# MK66F18 register map
Vendor: NXP Semiconductors; Series: Kinetis_K; File version: 1.6
CPU: CM4 r0p1, little endian, no MPU, FPU, VTOR, 4 interrupt priority bits
Registers are 32-bit, read-write, reset 0x0 unless marked. A register's access mark holds for its fields unless they carry their own. Offsets are from the block's base; [hi:lo] are bit positions; {n}, {i} and the like mark numbered series.

## CMT — Carrier Modulator Transmitter
Base 0x40062000; register names take the prefix CMT_
0x00 CGH1 8-bit reset not defined — CMT Carrier Generator High Data Register 1
  [7:0] PH — Primary Carrier High Time Data Value
0x01 CGL1 8-bit reset not defined — CMT Carrier Generator Low Data Register 1
  [7:0] PL — Primary Carrier Low Time Data Value
0x02 CGH2 8-bit reset not defined — CMT Carrier Generator High Data Register 2
  [7:0] SH — Secondary Carrier High Time Data Value
0x03 CGL2 8-bit reset not defined — CMT Carrier Generator Low Data Register 2
  [7:0] SL — Secondary Carrier Low Time Data Value
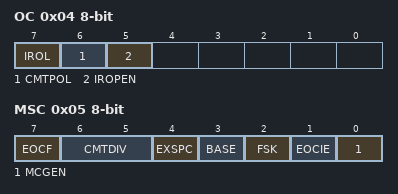
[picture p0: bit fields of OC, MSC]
0x04 OC 8-bit — CMT Output Control Register
  [7] IROL — IRO Latch Control
  [6] CMTPOL — CMT Output Polarity
    0=The IRO signal is active-low; 1=The IRO signal is active-high
  [5] IROPEN — IRO Pin Enable
    0=The IRO signal is disabled; 1=The IRO signal is enabled as output
0x05 MSC 8-bit — CMT Modulator Status and Control Register
  [7] EOCF ro — End Of Cycle Status Flag
    0=End of modulation cycle has not occurred since the flag last cleared; 1=End of modulator cycle has occurred
  [6:5] CMTDIV — CMT Clock Divide Prescaler
    0=IF * 1; 1=IF * 2; 2=IF * 4; 3=IF * 8
  [4] EXSPC — Extended Space Enable
    0=Extended space is disabled; 1=Extended space is enabled
  [3] BASE — Baseband Enable
    0=Baseband mode is disabled; 1=Baseband mode is enabled
  [2] FSK — FSK Mode Select
    0=The CMT operates in Time or Baseband mode; 1=The CMT operates in FSK mode
  [1] EOCIE — End of Cycle Interrupt Enable
    0=CPU interrupt is disabled; 1=CPU interrupt is enabled
  [0] MCGEN — Modulator and Carrier Generator Enable
    0=Modulator and carrier generator disabled; 1=Modulator and carrier generator enabled
0x06 CMD1 8-bit reset not defined — CMT Modulator Data Register Mark High
  [7:0] MB — MB[15:8]
0x07 CMD2 8-bit reset not defined — CMT Modulator Data Register Mark Low
  [7:0] MB — MB[7:0]
0x08 CMD3 8-bit reset not defined — CMT Modulator Data Register Space High
  [7:0] SB — SB[15:8]
0x09 CMD4 8-bit reset not defined — CMT Modulator Data Register Space Low
  [7:0] SB — SB[7:0]
0x0A PPS 8-bit — CMT Primary Prescaler Register
  [3:0] PPSDIV — Primary Prescaler Divider
    {v}=Bus clock * {v+1} (v=0..15)
0x0B DMA 8-bit — CMT Direct Memory Access Register
  [0] DMA — DMA Enable
    0=DMA transfer request and done are disabled; 1=DMA transfer request and done are enabled

## OSC — Oscillator
Base 0x40065000; register names take the prefix OSC_
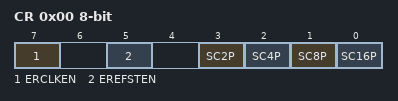
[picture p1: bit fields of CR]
0x00 CR 8-bit — OSC Control Register
  [7] ERCLKEN — External Reference Enable
    0=External reference clock is inactive; 1=External reference clock is enabled
  [5] EREFSTEN — External Reference Stop Enable
    0=External reference clock is disabled in Stop mode; 1=External reference clock stays enabled in Stop mode if ERCLKEN is set before entering Stop mode
  [3] SC2P — Oscillator 2 pF Capacitor Load Configure
    0=Disable the selection; 1=Add 2 pF capacitor to the oscillator load
  [2] SC4P — Oscillator 4 pF Capacitor Load Configure
    0=Disable the selection; 1=Add 4 pF capacitor to the oscillator load
  [1] SC8P — Oscillator 8 pF Capacitor Load Configure
    0=Disable the selection; 1=Add 8 pF capacitor to the oscillator load
  [0] SC16P — Oscillator 16 pF Capacitor Load Configure
    0=Disable the selection; 1=Add 16 pF capacitor to the oscillator load
0x02 DIV 8-bit — OSC_DIV
  [7:6] ERPS — ERCLK prescaler
    0=The divisor ratio is 1; 1=The divisor ratio is 2; 2=The divisor ratio is 4; 3=The divisor ratio is 8

## VREF — Voltage Reference
Base 0x40074000; register names take the prefix VREF_
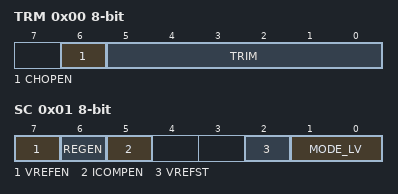
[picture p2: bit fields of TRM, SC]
0x00 TRM 8-bit (reset mask 0x40) — VREF Trim Register
  [6] CHOPEN — Chop oscillator enable. When set, internal chopping operation is enabled and the internal analog offset will be minimized.
    0=Chop oscillator is disabled; 1=Chop oscillator is enabled
  [5:0] TRIM — Trim bits
    0=Min; 63=Max
0x01 SC 8-bit — VREF Status and Control Register
  [7] VREFEN — Internal Voltage Reference enable
    0=The module is disabled; 1=The module is enabled
  [6] REGEN — Regulator enable
    0=Internal 1.75 V regulator is disabled; 1=Internal 1.75 V regulator is enabled
  [5] ICOMPEN — Second order curvature compensation enable
    0=Disabled; 1=Enabled
  [2] VREFST ro — Internal Voltage Reference stable
    0=The module is disabled or not stable; 1=The module is stable
  [1:0] MODE_LV — Buffer Mode selection
    0=Bandgap on only, for stabilization and startup; 1=High power buffer mode enabled; 2=Low-power buffer mode enabled
